# nRF7140_graphics register map
Vendor: Nordic Semiconductor; Series: nRF71; File version: 1
CPU: CM33 r0p4, little endian, MPU, FPU, 3 interrupt priority bits, 480 interrupts
Registers are 32-bit, read-write, reset 0x0 unless marked. A register's access mark holds for its fields unless they carry their own. Offsets are from the block's base; [hi:lo] are bit positions; lines under a group give offsets from that group; {n}, {i} and the like mark numbered series; 'fields as' and 'values as' point back to an identical list.

## GLOBAL_ANTSWC_NS — Antenna switch controller 0
Base 0x4F8E9000
Same registers: GLOBAL_ANTSWC_S 0x5F8E9000
0x100 EVENTS_TXERROR — Event indicating that a concurrent TX error condition has occurred
  [0] EVENTS_TXERROR
    0=NotGenerated (Event not generated); 1=Generated (Event generated)
0x104 EVENTS_TXRXERROR — Event indicating that a concurrent TX-RX error condition has occurred
  [0] EVENTS_TXRXERROR
    values as EVENTS_TXERROR.EVENTS_TXERROR
0x108 EVENTS_ANTSWCHANGED — Event indicating that the AntSw signal has changed
  [0] EVENTS_ANTSWCHANGED
    values as EVENTS_TXERROR.EVENTS_TXERROR
0x10C EVENTS_LNASWCHANGED — Event indicating that the LnaSw signal has changed
  [0] EVENTS_LNASWCHANGED
    values as EVENTS_TXERROR.EVENTS_TXERROR
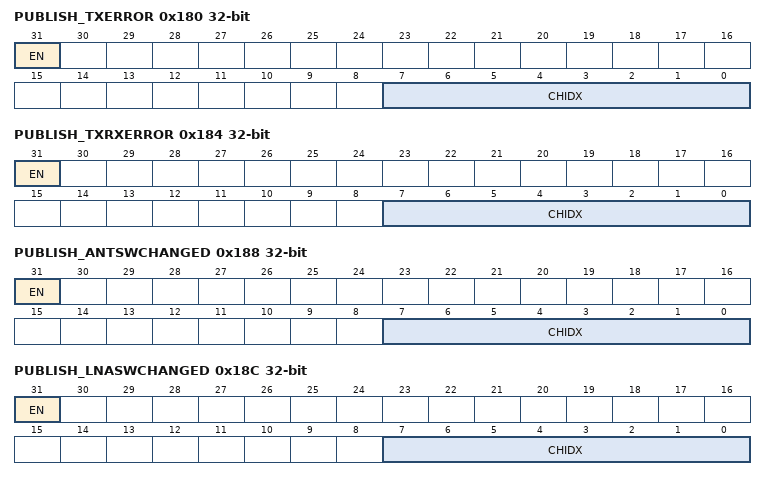
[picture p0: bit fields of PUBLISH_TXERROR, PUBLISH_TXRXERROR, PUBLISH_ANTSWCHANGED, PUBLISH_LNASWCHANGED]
0x180 PUBLISH_TXERROR — Publish configuration for event TXERROR
  [31] EN
    0=Disabled (Disable publishing); 1=Enabled (Enable publishing)
  [7:0] CHIDX — DPPI channel that event TXERROR will publish to
0x184 PUBLISH_TXRXERROR — Publish configuration for event TXRXERROR
  [31] EN
    values as PUBLISH_TXERROR.EN
  [7:0] CHIDX — DPPI channel that event TXRXERROR will publish to
0x188 PUBLISH_ANTSWCHANGED — Publish configuration for event ANTSWCHANGED
  [31] EN
    values as PUBLISH_TXERROR.EN
  [7:0] CHIDX — DPPI channel that event ANTSWCHANGED will publish to
0x18C PUBLISH_LNASWCHANGED — Publish configuration for event LNASWCHANGED
  [31] EN
    values as PUBLISH_TXERROR.EN
  [7:0] CHIDX — DPPI channel that event LNASWCHANGED will publish to
0x400 ERRORSTATUS group — Unspecified
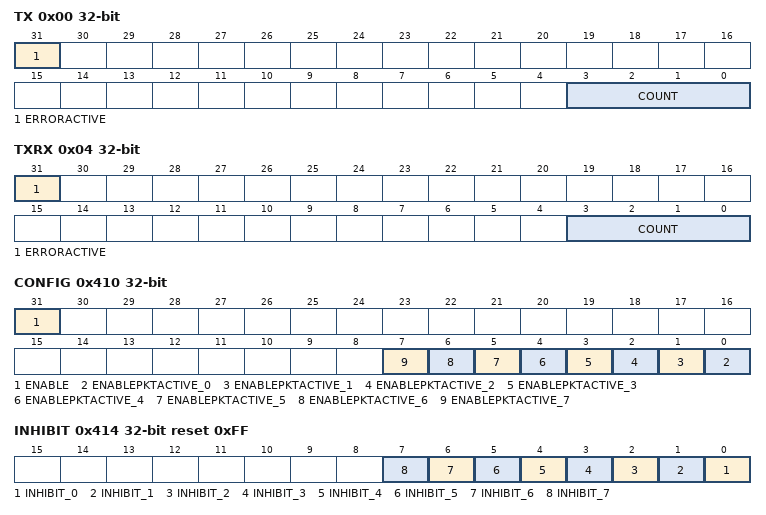
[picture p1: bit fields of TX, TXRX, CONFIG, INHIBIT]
  0x00 TX — Concurrent TX error condition
    [31] ERRORACTIVE ro — Concurrent TX error condition is active
    [3:0] COUNT — Count of concurrent TX error conditions detected
  0x04 TXRX — Concurrent TX-RX error condition
    [31] ERRORACTIVE ro — Concurrent TX-RX error condition is active
    [3:0] COUNT — Count of concurrent TX-RX error conditions detected
  0x08 ERRORPORT — Indicates which ports are in error
    [7:0] ERRORPORT — Bitfield indicating the ports in error during the last error condition.
0x410 CONFIG — Antenna switch controller enable / software reset
  [31] ENABLE — Enable antenna switch module.
    0=Disable (Antenna Switch Controller disabled - all outputs held low); 1=Enable (Antenna Switch Controller enabled)
  [n] ENABLEPKTACTIVE_{n} (n=0..7) — Bitfield indicating whether ANTSWC listens to PktActive on radio port i.
    0=Ignore PktActive on the corresponding radio port; 1=Respect (Use PktActive on the corresponding radio port for antenna switch selection)
0x414 INHIBIT reset 0xFF
  [all] fields
    0=Inhibit connection of antenna to the corresponding radio; 1=Enable antenna to be connected to the corresponding radio
  [n] INHIBIT_{n} (n=0..7) — Bitfield of 8 separate bits indicating whether connection of the antenna to radio on radio port i is enabled or inhibited.
0x500 OVERRIDE group — Unspecified
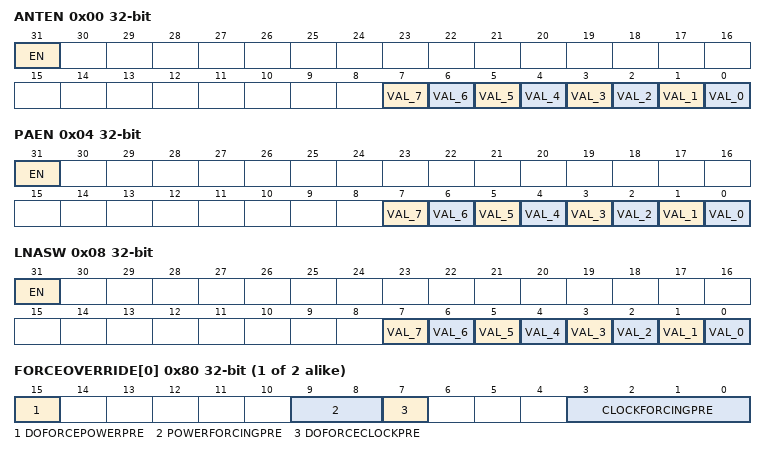
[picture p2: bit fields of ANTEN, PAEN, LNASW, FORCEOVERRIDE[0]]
  0x00 ANTEN — Override antenna switch (AntEn) output signals
    [31] EN
      0=Disable (Override is disabled); 1=Enable (Override is enabled)
    [n] VAL_{n} (n=0..7) — Override value for AntEn[i]. Note only one bit should be set. Where multiple bits are set the AntSw signal value is set to 0
      0=Clear the corresponding bit in AntEn; 1=Set (Assert the corresponding bit in AntEn)
  0x04 PAEN — Override power amplifier enable (PaEn) output signals
    [31] EN
      values as OVERRIDE.ANTEN.EN
    [n] VAL_{n} (n=0..7) — Override value for the signal PAEn[i]
      0=Clear the corresponding bit in PAEn; 1=Set (Assert the corresponding bit in PAEn)
  0x08 LNASW — Override shared LNA switch (LnaSw) output signals
    [31] EN
      values as OVERRIDE.ANTEN.EN
    [n] VAL_{n} (n=0..7) — Override value for the signal LnaSw[i]
      0=Clear the corresponding bit in LnaSw; 1=Set (Assert the corresponding bit in LnaSw)
0xF00 PCGCSLAVE group — Unspecified
  {0x0+4j} PENALTY[{j}] (j=0..1) — Description collection: Penalty level for power/clock pair n
    [7:0] PENALTY — Penalty level
  {0x80+4j} FORCEOVERRIDE[{j}] (j=0..1) — Description collection: Force override of power/clock pair n
    [15] DOFORCEPOWERPRE, [9:8] POWERFORCINGPRE, [7] DOFORCECLOCKPRE, [3:0] CLOCKFORCINGPRE
